# LPC15xx register map
File version: 0.7
CPU: CM3 r2p1, little endian, no MPU, no FPU, 3 interrupt priority bits
Registers are 32-bit, read-write, reset 0x0 unless marked. A register's access mark holds for its fields unless they carry their own. Offsets are from the block's base; [hi:lo] are bit positions; {n}, {i} and the like mark numbered series; 'fields as' and 'values as' point back to an identical list.

## IOCON — I/O pin configuration (IOCON)
Base 0x400F8000
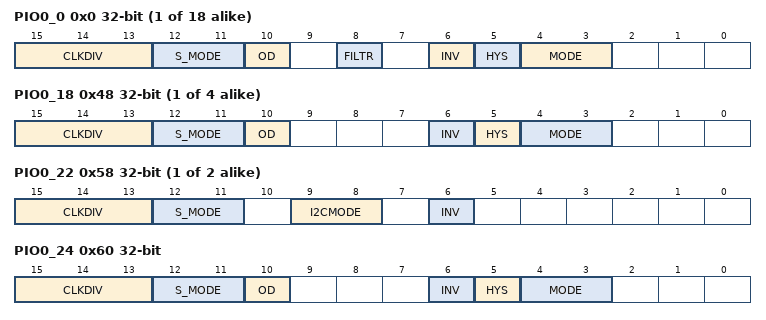
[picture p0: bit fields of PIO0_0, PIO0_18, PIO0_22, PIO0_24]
{0x0+4i} PIO0_{i} (i=0..17) reset not defined — Digital I/O control for port 0 pins PIO0_0 to PIO0_17. With glitch filter.
  [15:13] CLKDIV — Select peripheral clock divider for input filter sampling clock IOCONCLKDIV. Value 0x7 is reserved.
    0=CMP_PCLK; 1=CMP_PCLKDIV2 (CMP_PCLK/2.); 2=CMP_PCLKDIV4 (CMP_PCLK/4.); 3=CMP_PCLKDIV8 (CMP_PCLK/8.); 4=CMP_PCLKDIV16 (CMP_PCLK/16.); 5=CMP_PCLKDIV32 (CMP_PCLK/32.); 6=CMP_PCLKDIV64 (CMP_PCLK/64.)
  [12:11] S_MODE — Digital filter sample mode.
    0=BYPASS_INPUT_FILTER; 1=1_CLOCK_CYCLE (1 clock cycle. Input pulses shorter than one filter clock are rejected.); 2=2_CLOCK_CYCLES (2 clock cycles. Input pulses shorter than two filter clocks are rejected.); 3=3_CLOCK_CYCLES (3 clock cycles. Input pulses shorter than three filter clocks are rejected.)
  [10] OD — Open-drain mode.
    0=DISABLE; 1=OPEN_DRAIN_MODE_ENAB (Open-drain mode enabled. This is not a true open-drain mode.)
  [8] FILTR — Selects 10 ns input glitch filter.
    0=FILTER_ENABLED_; 1=FILTER_DISABLED_
  [6] INV — Invert input
    0=INPUT_NOT_INVERTED (Input not inverted (HIGH on pin reads as 1; LOW on pin reads as 0).); 1=INPUT_INVERTED_HIGH (Input inverted (HIGH on pin reads as 0, LOW on pin reads as 1).)
  [5] HYS — Hysteresis.
    0=DISABLE; 1=ENABLE
  [4:3] MODE — Selects function mode (on-chip pull-up/pull-down resistor control).
    0=INACTIVE_NO_PULL_DO (Inactive (no pull-down/pull-up resistor enabled).); 1=PULL_DOWN_RESISTOR_E (Pull-down resistor enabled.); 2=PULL_UP_RESISTOR_ENA (Pull-up resistor enabled.); 3=REPEATER_MODE
{0x0+4i} PIO0_{i} (i=18..21) reset not defined — Digital I/O control for port 0 pins PIO0_18 to PIO0_21. Without glitch filter.
  [15:13] CLKDIV — Select peripheral clock divider for input filter sampling clock IOCONCLKDIV. Value 0x7 is reserved.
    values as PIO0_0.CLKDIV
  [12:11] S_MODE — Digital filter sample mode.
    values as PIO0_0.S_MODE
  [10] OD — Open-drain mode.
    values as PIO0_0.OD
  [6] INV — Invert input
    values as PIO0_0.INV
  [5] HYS — Hysteresis.
    0=DISABLE; 1=ENABLE
  [4:3] MODE — Selects function mode (on-chip pull-up/pull-down resistor control).
    values as PIO0_0.MODE
{0x0+4i} PIO0_{i} (i=22..23) reset not defined — I/O control for open-drain pin PIO0_22. This pin is used for the I2C-bus SCL function.
  [15:13] CLKDIV — Select peripheral clock divider for input filter sampling clock IOCONCLKDIV. Value 0x7 is reserved.
    values as PIO0_0.CLKDIV
  [12:11] S_MODE — Digital filter sample mode.
    values as PIO0_0.S_MODE
  [9:8] I2CMODE — Selects I2C mode. Select Standard mode (I2CMODE = 00, default) or Standard I/O functionality (I2CMODE = 01) if the pin function is GPIO (FUNC = 000).
    0=STANDARD_MODE (Standard mode/ Fast-mode I2C.); 1=STANDARD_IO_FUNCTIO (Standard I/O functionality); 2=FAST_MODE_PLUS_I2C
  [6] INV — Invert input
    values as PIO0_0.INV
{0x0+4i} PIO0_{i} (i=24..24) reset not defined — Digital I/O control for port 0 pins PIO0_24. Without glitch filter.
  fields as PIO0_18
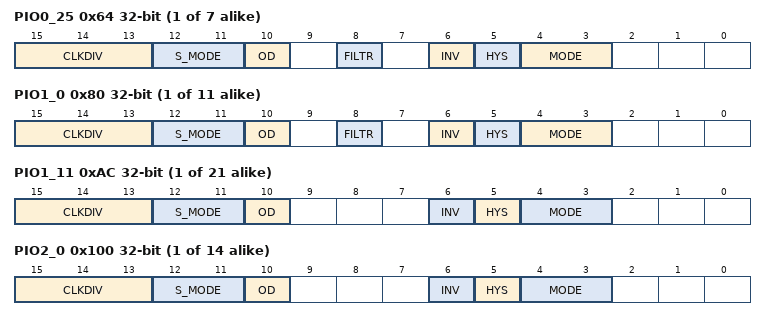
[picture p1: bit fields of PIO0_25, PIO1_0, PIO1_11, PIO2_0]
{0x0+4i} PIO0_{i} (i=25..31) reset not defined — Digital I/O control for port 0 pins PIO0_25 to PIO0_31. With glitch filter.
  fields as PIO0_0
{0x80+4i} PIO1_{i} (i=0..10) reset not defined — Digital I/O control for port 1 pins PIO1_0 to PIO1_10. With glitch filter.
  fields as PIO0_0
{0x80+4i} PIO1_{i} (i=11..31) reset not defined — Digital I/O control for port 1 pins PIO1_11 to PIO1_31. Without glitch filter.
  fields as PIO0_18
{0x100+4i} PIO2_{i} (i=0..13) reset not defined — Digital I/O control for port 2 pins PIO2_0 to PIO2_13. Without glitch filter.
  fields as PIO0_18
